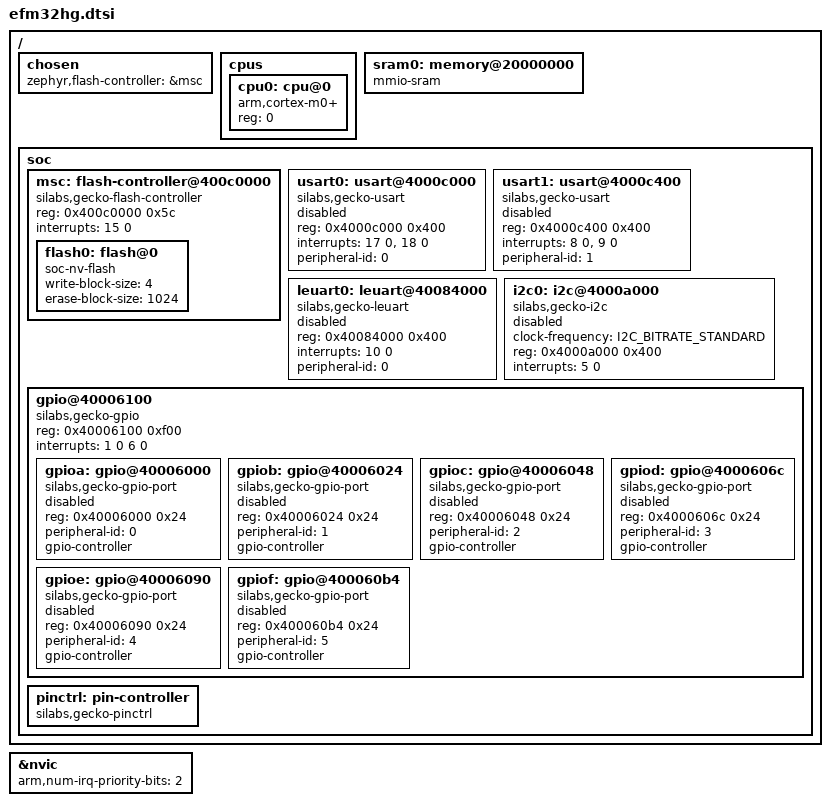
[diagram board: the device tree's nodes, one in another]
/* SPDX-License-Identifier: Apache-2.0 */

#include <arm/armv6-m.dtsi>
#include <zephyr/dt-bindings/gpio/gpio.h>
#include <zephyr/dt-bindings/i2c/i2c.h>
#include "gpio_gecko.h"

/ {
	chosen {
		zephyr,flash-controller = &msc;
	};

	cpus {
		#address-cells = <1>;
		#size-cells = <0>;

		cpu0: cpu@0 {
			compatible = "arm,cortex-m0+";
			reg = <0>;
		};
	};

	sram0: memory@20000000 {
		compatible = "mmio-sram";
	};

	soc {
		msc: flash-controller@400c0000 {
			compatible = "silabs,gecko-flash-controller";
			reg = <0x400c0000 0x5c>;
			interrupts = <15 0>;

			#address-cells = <1>;
			#size-cells = <1>;

			flash0: flash@0 {
				compatible = "soc-nv-flash";
				write-block-size = <4>;
				erase-block-size = <1024>;
			};
		};

		usart0: usart@4000c000 { /* USART0 */
			compatible = "silabs,gecko-usart";
			reg = <0x4000c000 0x400>;
			interrupts = <17 0>, <18 0>;
			interrupt-names = "rx", "tx";
			peripheral-id = <0>;
			status = "disabled";
		};

		usart1: usart@4000c400 { /* USART1 */
			compatible = "silabs,gecko-usart";
			reg = <0x4000c400 0x400>;
			interrupts = <8 0>, <9 0>;
			interrupt-names = "rx", "tx";
			peripheral-id = <1>;
			status = "disabled";
		};

		leuart0: leuart@40084000 { /* LEUART0 */
			compatible = "silabs,gecko-leuart";
			reg = <0x40084000 0x400>;
			interrupts = <10 0>;
			peripheral-id = <0>;
			status = "disabled";
		};

		i2c0: i2c@4000a000 {
			compatible = "silabs,gecko-i2c";
			clock-frequency = <I2C_BITRATE_STANDARD>;
			#address-cells = <1>;
			#size-cells = <0>;
			reg = <0x4000a000 0x400>;
			interrupts = <5 0>;
			status = "disabled";
		};

		gpio@40006100 {
			compatible = "silabs,gecko-gpio";
			reg = <0x40006100 0xf00>;
			interrupts = <1 0 6 0>;
			interrupt-names = "GPIO_EVEN", "GPIO_ODD";

			ranges;
			#address-cells = <1>;
			#size-cells = <1>;

			gpioa: gpio@40006000 {
				compatible = "silabs,gecko-gpio-port";
				reg = <0x40006000 0x24>;
				peripheral-id = <0>;
				gpio-controller;
				#gpio-cells = <2>;
				status = "disabled";
			};

			gpiob: gpio@40006024 {
				compatible = "silabs,gecko-gpio-port";
				reg = <0x40006024 0x24>;
				peripheral-id = <1>;
				gpio-controller;
				#gpio-cells = <2>;
				status = "disabled";
			};

			gpioc: gpio@40006048 {
				compatible = "silabs,gecko-gpio-port";
				reg = <0x40006048 0x24>;
				peripheral-id = <2>;
				gpio-controller;
				#gpio-cells = <2>;
				status = "disabled";
			};

			gpiod: gpio@4000606c {
				compatible = "silabs,gecko-gpio-port";
				reg = <0x4000606c 0x24>;
				peripheral-id = <3>;
				gpio-controller;
				#gpio-cells = <2>;
				status = "disabled";
			};

			gpioe: gpio@40006090 {
				compatible = "silabs,gecko-gpio-port";
				reg = <0x40006090 0x24>;
				peripheral-id = <4>;
				gpio-controller;
				#gpio-cells = <2>;
				status = "disabled";
			};

			gpiof: gpio@400060b4 {
				compatible = "silabs,gecko-gpio-port";
				reg = <0x400060b4 0x24>;
				peripheral-id = <5>;
				gpio-controller;
				#gpio-cells = <2>;
				status = "disabled";
			};
		};

		pinctrl: pin-controller {
			/* Pin controller is a "virtual" device since SiLabs SoCs do pin
			 * control in a distributed way (GPIO registers and PSEL
			 * registers on each peripheral).
			 */
			compatible = "silabs,gecko-pinctrl";
		};
	};
};

&nvic {
	arm,num-irq-priority-bits = <2>;
};
